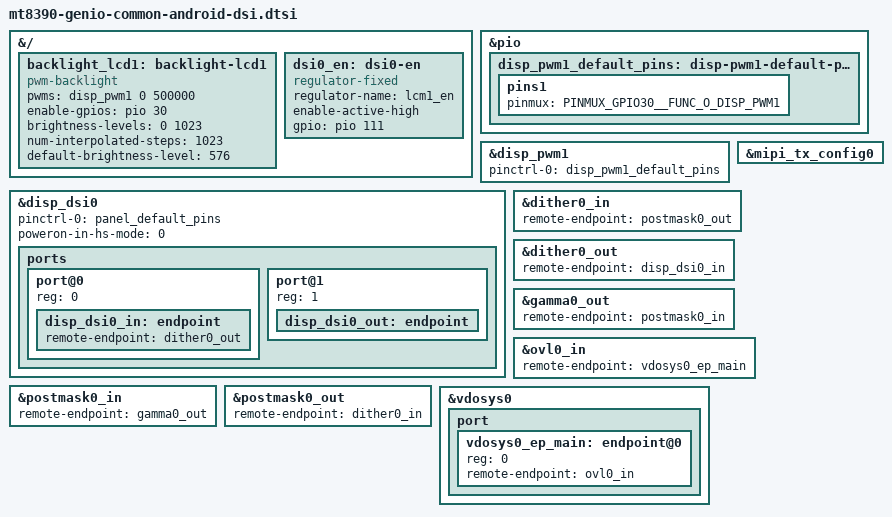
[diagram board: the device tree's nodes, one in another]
// SPDX-License-Identifier: GPL-2.0
/*
 * Copyright (c) 2025 BayLibre, SAS.
 * Author: Vitor Sato Eschholz <vsatoes@baylibre.com>
 */

/dts-v1/;
/plugin/;

#include <dt-bindings/gpio/gpio.h>
#include <dt-bindings/pinctrl/mediatek,mt8188-pinfunc.h>

#include "mt8390-genio-common-android.dtsi"

&{/} {
	backlight_lcd1: backlight-lcd1 {
		compatible = "pwm-backlight";
		pwms = <&disp_pwm1 0 500000>;
		enable-gpios = <&pio 30 GPIO_ACTIVE_HIGH>;
		brightness-levels = <0 1023>;
		num-interpolated-steps = <1023>;
		default-brightness-level = <576>;
	};

	dsi0_en: dsi0-en {
		compatible = "regulator-fixed";
		regulator-name = "lcm1_en";
		enable-active-high;
		gpio = <&pio 111 GPIO_ACTIVE_HIGH>;
	};
};

&pio {
	disp_pwm1_default_pins: disp-pwm1-default-pins {
		pins1 {
			pinmux = <PINMUX_GPIO30__FUNC_O_DISP_PWM1>;
		};
	};
};

&disp_pwm1 {
	pinctrl-names = "default";
	pinctrl-0 = <&disp_pwm1_default_pins>;
	status = "okay";
};

&mipi_tx_config0 {
	status = "okay";
};

&disp_dsi0 {
	pinctrl-names = "default";
	pinctrl-0 = <&panel_default_pins>;
	poweron-in-hs-mode = <0>;
	status = "okay";

	ports {
		#address-cells = <1>;
		#size-cells = <0>;

		port@0 {
			reg = <0>;
			disp_dsi0_in: endpoint {
				remote-endpoint = <&dither0_out>;
			};
		};

		port@1 {
			reg = <1>;
			disp_dsi0_out: endpoint { };
		};
	};
};

&dither0_in {
	remote-endpoint = <&postmask0_out>;
};

&dither0_out {
	remote-endpoint = <&disp_dsi0_in>;
};

&gamma0_out {
	remote-endpoint = <&postmask0_in>;
};

&ovl0_in {
	remote-endpoint = <&vdosys0_ep_main>;
};

&postmask0_in {
	remote-endpoint = <&gamma0_out>;
};

&postmask0_out {
	remote-endpoint = <&dither0_in>;
};

&vdosys0 {
	port {
		#address-cells = <1>;
		#size-cells = <0>;

		vdosys0_ep_main: endpoint@0 {
			reg = <0>;
			remote-endpoint = <&ovl0_in>;
		};
	};
};
